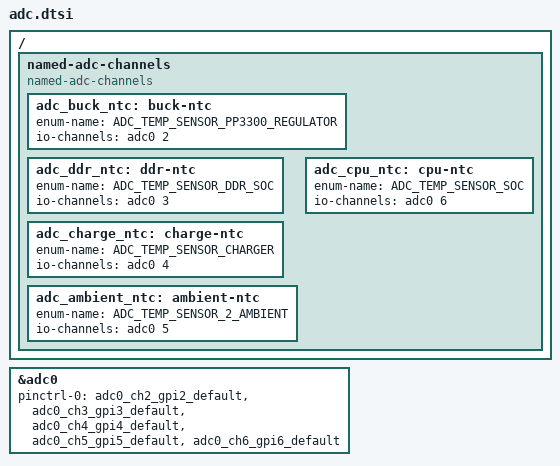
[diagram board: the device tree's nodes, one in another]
/* Copyright 2026 The ChromiumOS Authors
 * Use of this source code is governed by a BSD-style license that can be
 * found in the LICENSE file.
 */

/ {
	named-adc-channels {
		compatible = "named-adc-channels";

		adc_buck_ntc: buck-ntc {
			enum-name = "ADC_TEMP_SENSOR_PP3300_REGULATOR";
			io-channels = <&adc0 2>;
		};
		adc_ddr_ntc: ddr-ntc {
			enum-name = "ADC_TEMP_SENSOR_DDR_SOC";
			io-channels = <&adc0 3>;
		};
		adc_charge_ntc: charge-ntc {
			enum-name = "ADC_TEMP_SENSOR_CHARGER";
			io-channels = <&adc0 4>;
		};
		adc_ambient_ntc: ambient-ntc {
			enum-name = "ADC_TEMP_SENSOR_2_AMBIENT";
			io-channels = <&adc0 5>;
		};
		adc_cpu_ntc: cpu-ntc {
			enum-name = "ADC_TEMP_SENSOR_SOC";
			io-channels = <&adc0 6>;
		};
	};
};

&adc0 {
	status = "okay";
	pinctrl-0 = <&adc0_ch2_gpi2_default
		&adc0_ch3_gpi3_default
		&adc0_ch4_gpi4_default
		&adc0_ch5_gpi5_default
		&adc0_ch6_gpi6_default>;
	pinctrl-names = "default";
};
